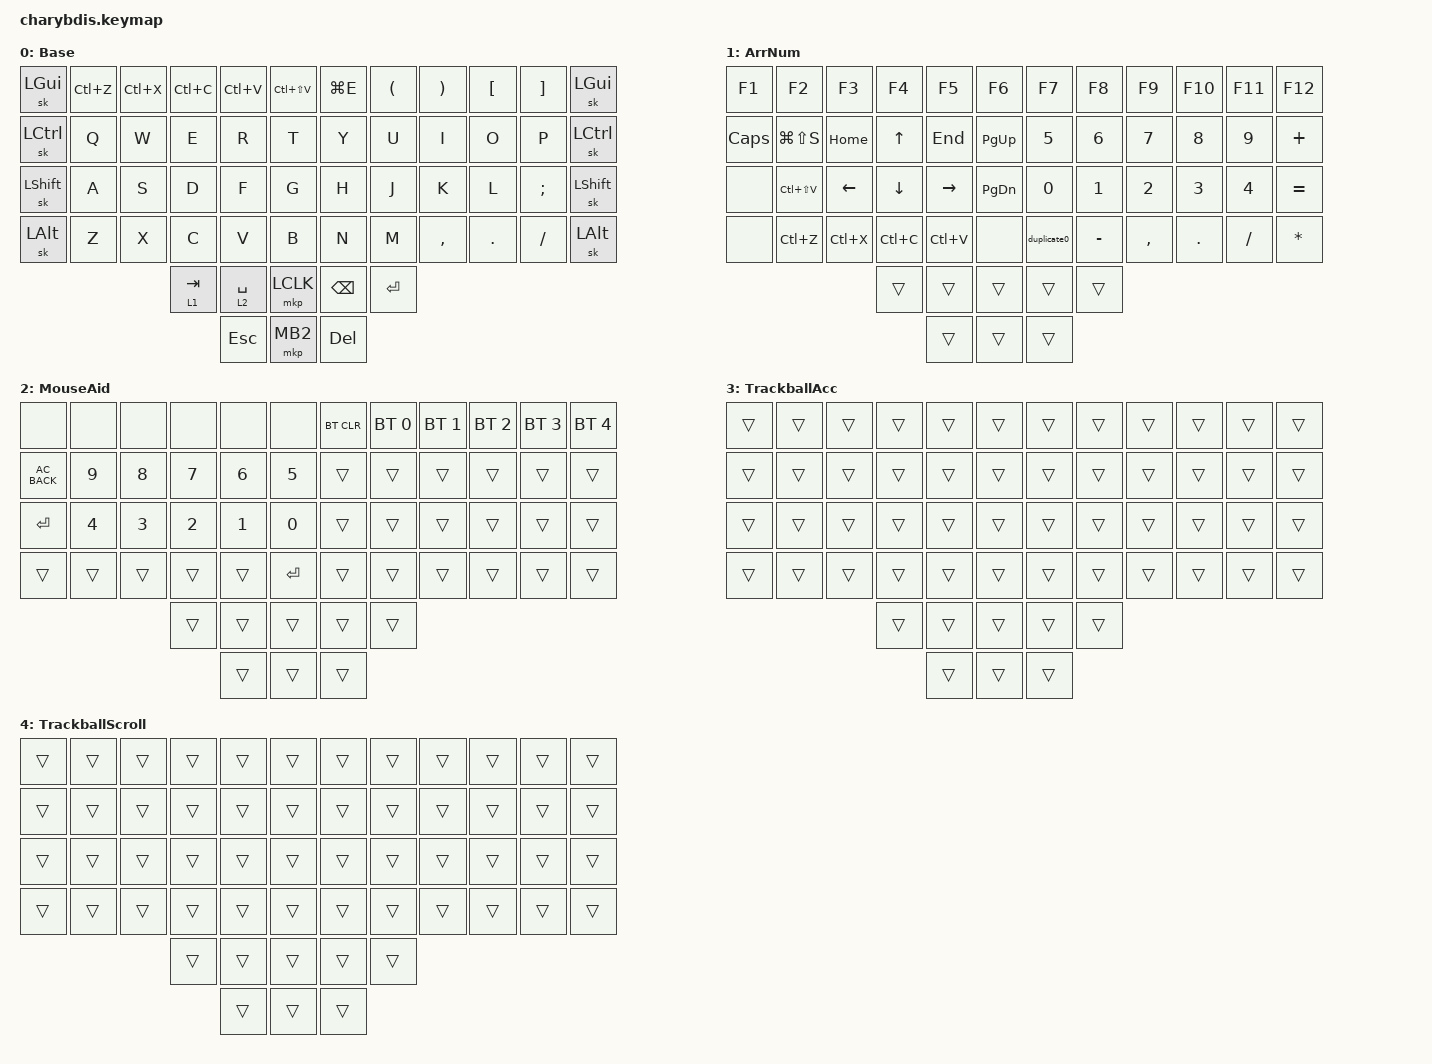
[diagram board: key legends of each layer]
#include <behaviors.dtsi>
#include <dt-bindings/zmk/keys.h>
#include <dt-bindings/zmk/bt.h>
#include <dt-bindings/zmk/mouse.h>
#include <dt-bindings/zmk/pointing.h>

/* 1. 글로벌 설정 */
&lt {
    tapping-term-ms = <200>;
    flavor = "balanced";
    quick-tap-ms = <150>;
};

    macros {
        duplicate0: duplicate0 {
            compatible = "zmk,behavior-macro";
            #binding-cells = <0>;
            bindings = <&kp N0 &kp N0>;
            label = "DUPLICATE0";
        };
    };

   keymap {
        compatible = "zmk,keymap";

        Base {
            bindings = <
&sk LEFT_GUI    &kp LC(Z)  &kp LC(X)  &kp LC(C)  &kp LC(V)    &kp LC(LS(V))    &kp LG(E)      &kp LEFT_PARENTHESIS  &kp RIGHT_PARENTHESIS  &kp LBKT    &kp RBKT  &sk LEFT_GUI
&sk LCTRL       &kp Q      &kp W      &kp E      &kp R        &kp T            &kp Y          &kp U                 &kp I                  &kp O       &kp P     &sk LCTRL
&sk LEFT_SHIFT  &kp A      &kp S      &kp D      &kp F        &kp G            &kp H          &kp J                 &kp K                  &kp L       &kp SEMI  &sk LEFT_SHIFT
&sk LEFT_ALT    &kp Z      &kp X      &kp C      &kp V        &kp B            &kp N          &kp M                 &kp COMMA              &kp PERIOD  &kp FSLH  &sk LALT
                                      &lt 1 TAB  &lt 2 SPACE  &mkp LCLK        &kp BACKSPACE  &kp ENTER
                                                 &kp ESCAPE   &mkp MB2         &kp DEL
            >;

       
        };

        ArrNum {
            bindings = <
&kp F1    &kp F2         &kp F3          &kp F4          &kp F5           &kp F6           &kp F7       &kp F8        &kp F9        &kp F10       &kp F11       &kp F12
&kp CAPS  &kp LG(LS(S))  &kp HOME        &kp UP_ARROW    &kp END          &kp PG_UP        &kp N5       &kp NUMBER_6  &kp N7        &kp N8        &kp N9        &kp PLUS
&none     &kp LC(LS(V))  &kp LEFT_ARROW  &kp DOWN_ARROW  &kp RIGHT_ARROW  &kp PAGE_DOWN    &kp N0       &kp NUMBER_1  &kp NUMBER_2  &kp NUMBER_3  &kp NUMBER_4  &kp EQUAL
&none     &kp LC(Z)      &kp LC(X)       &kp LC(C)       &kp LC(V)        &none            &duplicate0  &kp MINUS     &kp COMMA     &kp DOT       &kp SLASH     &kp ASTERISK
                                         &trans          &trans           &trans           &trans       &trans
                                                         &trans           &trans           &trans
            >;

        };

        MouseAid {
            bindings = <
&none          &none   &none   &none   &none   &none        &bt BT_CLR  &bt BT_SEL 0  &bt BT_SEL 1  &bt BT_SEL 2  &bt BT_SEL 3  &bt BT_SEL 4
&kp C_AC_BACK  &kp N9  &kp N8  &kp N7  &kp N6  &kp N5       &trans      &trans        &trans        &trans        &trans        &trans
&kp ENTER      &kp N4  &kp N3  &kp N2  &kp N1  &kp N0       &trans      &trans        &trans        &trans        &trans        &trans
&trans         &trans  &trans  &trans  &trans  &kp ENTER    &trans      &trans        &trans        &trans        &trans        &trans
                               &trans  &trans  &trans       &trans      &trans
                                       &trans  &trans       &trans
            >;
        };

        TrackballAcc {
            bindings = <
&trans  &trans  &trans  &trans  &trans  &trans    &trans  &trans  &trans  &trans  &trans  &trans
&trans  &trans  &trans  &trans  &trans  &trans    &trans  &trans  &trans  &trans  &trans  &trans
&trans  &trans  &trans  &trans  &trans  &trans    &trans  &trans  &trans  &trans  &trans  &trans
&trans  &trans  &trans  &trans  &trans  &trans    &trans  &trans  &trans  &trans  &trans  &trans
                        &trans  &trans  &trans    &trans  &trans
                                &trans  &trans    &trans
            >;
        };

        TrackballScroll {
            bindings = <
&trans  &trans  &trans  &trans  &trans  &trans    &trans  &trans  &trans  &trans  &trans  &trans
&trans  &trans  &trans  &trans  &trans  &trans    &trans  &trans  &trans  &trans  &trans  &trans
&trans  &trans  &trans  &trans  &trans  &trans    &trans  &trans  &trans  &trans  &trans  &trans
&trans  &trans  &trans  &trans  &trans  &trans    &trans  &trans  &trans  &trans  &trans  &trans
                        &trans  &trans  &trans    &trans  &trans
                                &trans  &trans    &trans
            >;
        };

        /* layer_2 {
            bindings = <
&none  &none   &none    &none   &none         &none         &kp N1         &none         &none     &none  &none   &to 0
&none  &none   &none    &none   &none         &none         &none         &none          &rgb_ug RGB_BRD &rgb_ug RGB_BRI  &rgb_ug RGB_EFF   &rgb_ug RGB_TOG
&none  &none   &none    &none   &none         &none         &none         &mkp LCLK     &mkp RCLK  &none  &none   &none
&none  &none   &none    &none   &bt BT_NXT  &bt BT_CLR    &none         &none         &none     &none  &none   &none
                                   &none         &none         &none         &none         &none
                                                 &none         &none         &none
            >;

        };

       Mouse {
            bindings = <
&none        &none         &none         &none         &none      &none         &none       &none      &none         &none         &none         &none
&none        &bt BT_SEL 0  &bt BT_SEL 1  &bt BT_SEL 3  &none      &bt BT_CLR    &bt BT_CLR  &none      &bt BT_SEL 2  &bt BT_SEL 1  &bt BT_SEL 0  &none
&none        &trans        &trans        &mkp MCLK     &trans     &none         &none       &trans     &mkp MCLK     &trans        &trans        &none
&bootloader  &trans        &mkp RCLK     &mo 4         &mkp LCLK  &mo 5         &mo 5       &mkp LCLK  &mo 4         &mkp RCLK     &trans        &bootloader
                                         &mo 5         &mkp LCLK  &mkp RCLK     &mkp RCLK   &mkp LCLK
                                                       &none      &trans        &trans
            >;

            
        };

        layer_4 {
            bindings = <
&trans  &trans  &trans     &trans     &trans     &trans       &trans     &trans     &trans     &trans     &trans  &trans
&trans  &trans  &trans     &trans     &trans     &trans       &trans     &trans     &trans     &trans     &trans  &trans
&trans  &trans  &trans     &mkp MCLK  &trans     &trans       &trans     &trans     &mkp MCLK  &trans     &trans  &trans
&trans  &trans  &mkp RCLK  &trans     &mkp LCLK  &trans       &trans     &mkp LCLK  &trans     &mkp RCLK  &trans  &trans
                           &trans     &mkp LCLK  &mkp RCLK    &mkp RCLK  &mkp LCLK
                                      &trans     &trans       &trans
            >;
                
                

        };

        layer_5 {
            bindings = <
&trans  &trans  &trans     &trans     &trans     &trans       &trans     &trans     &trans     &trans     &trans  &trans
&trans  &trans  &trans     &trans     &trans     &trans       &trans     &trans     &trans     &trans     &trans  &trans
&trans  &trans  &trans     &mkp MCLK  &trans     &trans       &trans     &trans     &mkp MCLK  &trans     &trans  &trans
&trans  &trans  &mkp RCLK  &trans     &mkp LCLK  &trans       &trans     &mkp LCLK  &trans     &mkp RCLK  &trans  &trans
                           &trans     &mkp LCLK  &mkp RCLK    &mkp RCLK  &mkp LCLK
                                      &trans     &trans       &trans
            >;

                
        };*/
    };
};
